# PIC32MX270F512H register map
Vendor: Microchip
Registers are 32-bit, read-write, reset 0x0 unless marked. A register's access mark holds for its fields unless they carry their own. Addresses are absolute, and some are shared; only a register's first bit layout is shown; [hi:lo] are bit positions; {n}, {i} and the like mark numbered series; 'fields as' and 'values as' point back to an identical list.

## CONFIG — Configuration words, addresses in PhysicalSpace
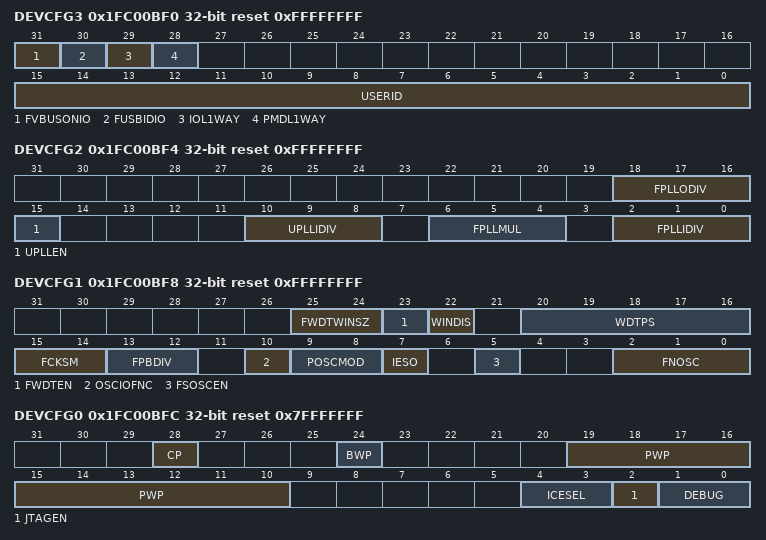
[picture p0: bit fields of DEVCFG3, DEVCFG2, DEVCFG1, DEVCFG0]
0x1FC00BF0 DEVCFG3 reset 0xFFFFFFFF
  [31] FVBUSONIO — USB VBUS ON Selection
    0=OFF (Controlled by Port Function); 1=ON (Controlled by USB Module)
  [30] FUSBIDIO — USB USID Selection
    0=OFF (Controlled by Port Function); 1=ON (Controlled by the USB Module)
  [29] IOL1WAY — Peripheral Pin Select Configuration
    1=ON (Allow only one reconfiguration); 0=OFF (Allow multiple reconfigurations)
  [28] PMDL1WAY — Peripheral Module Disable Configuration
    values as IOL1WAY
  [15:0] USERID
0x1FC00BF4 DEVCFG2 reset 0xFFFFFFFF
  [18:16] FPLLODIV — System PLL Output Clock Divider
    0=DIV_1 (PLL Divide by 1); 1=DIV_2 (PLL Divide by 2); 2=DIV_4 (PLL Divide by 4); 3=DIV_8 (PLL Divide by 8); 4=DIV_16 (PLL Divide by 16); 5=DIV_32 (PLL Divide by 32); 6=DIV_64 (PLL Divide by 64); 7=DIV_256 (PLL Divide by 256)
  [15] UPLLEN — USB PLL Enable
    0=ON (Enabled); 1=OFF (Disabled and Bypassed)
  [10:8] UPLLIDIV — USB PLL Input Divider
    {v}=DIV_{v+1} ({v+1}x Divider) (v=0..5); 6=DIV_10 (10x Divider); 7=DIV_12 (12x Divider)
  [6:4] FPLLMUL — PLL Multiplier
    {v}=MUL_{v+15} ({v+15}x Multiplier) (v=0..6); 7=MUL_24 (24x Multiplier)
  [2:0] FPLLIDIV — PLL Input Divider
    values as UPLLIDIV
0x1FC00BF8 DEVCFG1 reset 0xFFFFFFFF
  [25:24] FWDTWINSZ — Watchdog Timer Window Size
    0=WINSZ_75 (Window Size is 75%); 1=WINSZ_50 (Window Size is 50%); 2=WINSZ_37 (Window Size is 37.5%); 3=WINSZ_25 (Window Size is 25%)
  [23] FWDTEN — Watchdog Timer Enable
    0=OFF (WDT Disabled (SWDTEN Bit Controls)); 1=ON (WDT Enabled)
  [22] WINDIS — Watchdog Timer Window Enable
    0=ON (Watchdog Timer is in Window Mode); 1=OFF (Watchdog Timer is in Non-Window Mode)
  [20:16] WDTPS — Watchdog Timer Postscaler
    0=PS1 (1:1); 1=PS2 (1:2); 2=PS4 (1:4); 3=PS8 (1:8); 4=PS16 (1:16); 5=PS32 (1:32); 6=PS64 (1:64); 7=PS128 (1:128); 8=PS256 (1:256); 9=PS512 (1:512); 10=PS1024 (1:1024); 11=PS2048 (1:2048); 12=PS4096 (1:4096); 13=PS8192 (1:8192); 14=PS16384 (1:16384); 15=PS32768 (1:32768); 0b1x000=PS65536 (1:65536); 0b1x001=PS131072 (1:131072); 0b1x010=PS262144 (1:262144); 0b1x011=PS524288 (1:524288); 0b1x1xx=PS1048576 (1:1048576)
  [15:14] FCKSM — Clock Switching and Monitor Selection
    0=CSECME (Clock Switch Enable, FSCM Enabled); 1=CSECMD (Clock Switch Enable, FSCM Disabled); 3=CSDCMD (Clock Switch Disable, FSCM Disabled)
  [13:12] FPBDIV — Peripheral Clock Divisor
    0=DIV_1 (Pb_Clk is Sys_Clk/1); 1=DIV_2 (Pb_Clk is Sys_Clk/2); 2=DIV_4 (Pb_Clk is Sys_Clk/4); 3=DIV_8 (Pb_Clk is Sys_Clk/8)
  [10] OSCIOFNC — CLKO Output Signal Active on the OSCO Pin
    1=OFF (Disabled); 0=ON (Enabled)
  [9:8] POSCMOD — Primary Oscillator Configuration
    0=EC (External clock mode); 1=XT (XT osc mode); 2=HS (HS osc mode); 3=OFF (Primary osc disabled)
  [7] IESO — Internal/External Switch Over
    0=OFF (Disabled); 1=ON (Enabled)
  [5] FSOSCEN — Secondary Oscillator Enable
    0=OFF (Disabled); 1=ON (Enabled)
  [2:0] FNOSC — Oscillator Selection Bits
    0=FRC (Fast RC Osc (FRC)); 1=FRCPLL (Fast RC Osc with PLL); 2=PRI (Primary Osc (XT,HS,EC)); 3=PRIPLL (Primary Osc w/PLL (XT+,HS+,EC+PLL)); 4=SOSC (Low Power Secondary Osc (SOSC)); 5=LPRC (Low Power RC Osc (LPRC)); 6=FRCDIV16 (Fast RC Osc w/Div-by-16 (FRC/16)); 7=FRCDIV (Fast RC Osc w/Div-by-N (FRCDIV))
0x1FC00BFC DEVCFG0 reset 0x7FFFFFFF
  [28] CP — Code Protect
    0=ON (Protection Enabled); 1=OFF (Protection Disabled)
  [24] BWP — Boot Flash Write Protect bit
    0=ON (Protection Enabled); 1=OFF (Protection Disabled)
  [19:10] PWP — Program Flash Write Protect
    0x3FF=OFF (Disable); 0x3FE=PWP1K (First 1K); 0x3FD=PWP2K (First 2K); 0x3FC=PWP3K (First 3K); 0x3FB=PWP4K (First 4K); 0x3FA=PWP5K (First 5K); 0x3F9=PWP6K (First 6K); 0x3F8=PWP7K (First 7K); 0x3F7=PWP8K (First 8K); 0x3F6=PWP9K (First 9K); 0x3F5=PWP10K (First 10K); 0x3F4=PWP11K (First 11K); 0x3F3=PWP12K (First 12K); 0x3F2=PWP13K (First 13K); 0x3F1=PWP14K (First 14K); 0x3F0=PWP15K (First 15K); 0x3EF=PWP16K (First 16K); 0x3EE=PWP17K (First 17K); 0x3ED=PWP18K (First 18K); 0x3EC=PWP19K (First 19K); 0x3EB=PWP20K (First 20K); 0x3EA=PWP21K (First 21K); 0x3E9=PWP22K (First 22K); 0x3E8=PWP23K (First 23K); 0x3E7=PWP24K (First 24K); 0x3E6=PWP25K (First 25K); 0x3E5=PWP26K (First 26K); 0x3E4=PWP27K (First 27K); 0x3E3=PWP28K (First 28K); 0x3E2=PWP29K (First 29K); 0x3E1=PWP30K (First 30K); 0x3E0=PWP31K (First 31K); 0x3DF=PWP32K (First 32K); 0x3DE=PWP33K (First 33K); 0x3DD=PWP34K (First 34K); 0x3DC=PWP35K (First 35K); 0x3DB=PWP36K (First 36K); 0x3DA=PWP37K (First 37K); 0x3D9=PWP38K (First 38K); 0x3D8=PWP39K (First 39K); 0x3D7=PWP40K (First 40K); 0x3D6=PWP41K (First 41K); 0x3D5=PWP42K (First 42K); 0x3D4=PWP43K (First 43K); 0x3D3=PWP44K (First 44K); 0x3D2=PWP45K (First 45K); 0x3D1=PWP46K (First 46K); 0x3D0=PWP47K (First 47K); 0x3CF=PWP48K (First 48K); 0x3CE=PWP49K (First 49K); 0x3CD=PWP50K (First 50K); 0x3CC=PWP51K (First 51K); 0x3CB=PWP52K (First 52K); 0x3CA=PWP53K (First 53K); 0x3C9=PWP54K (First 54K); 0x3C8=PWP55K (First 55K); 0x3C7=PWP56K (First 56K); 0x3C6=PWP57K (First 57K); 0x3C5=PWP58K (First 58K); 0x3C4=PWP59K (First 59K); 0x3C3=PWP60K (First 60K); 0x3C2=PWP61K (First 61K); 0x3C1=PWP62K (First 62K); 0x3C0=PWP63K (First 63K); 0x3BF=PWP64K (First 64K); 0x3BE=PWP65K (First 65K); 0x3BD=PWP66K (First 66K); 0x3BC=PWP67K (First 67K); 0x3BB=PWP68K (First 68K); 0x3BA=PWP69K (First 69K); 0x3B9=PWP70K (First 70K); 0x3B8=PWP71K (First 71K); 0x3B7=PWP72K (First 72K); 0x3B6=PWP73K (First 73K); 0x3B5=PWP74K (First 74K); 0x3B4=PWP75K (First 75K); 0x3B3=PWP76K (First 76K); 0x3B2=PWP77K (First 77K); 0x3B1=PWP78K (First 78K); 0x3B0=PWP79K (First 79K); 0x3AF=PWP80K (First 80K); 0x3AE=PWP81K (First 81K); 0x3AD=PWP82K (First 82K); 0x3AC=PWP83K (First 83K); 0x3AB=PWP84K (First 84K); 0x3AA=PWP85K (First 85K); 0x3A9=PWP86K (First 86K); 0x3A8=PWP87K (First 87K); 0x3A7=PWP88K (First 88K); 0x3A6=PWP89K (First 89K); 0x3A5=PWP90K (First 90K); 0x3A4=PWP91K (First 91K); 0x3A3=PWP92K (First 92K); 0x3A2=PWP93K (First 93K); 0x3A1=PWP94K (First 94K); 0x3A0=PWP95K (First 95K); 0x39F=PWP96K (First 96K); 0x39E=PWP97K (First 97K); 0x39D=PWP98K (First 98K); 0x39C=PWP99K (First 99K); 0x39B=PWP100K (First 100K); 0x39A=PWP101K (First 101K); 0x399=PWP102K (First 102K); 0x398=PWP103K (First 103K); 0x397=PWP104K (First 104K); 0x396=PWP105K (First 105K); 0x395=PWP106K (First 106K); 0x394=PWP107K (First 107K); 0x393=PWP108K (First 108K); 0x392=PWP109K (First 109K); 0x391=PWP110K (First 110K); 0x390=PWP111K (First 111K); 0x38F=PWP112K (First 112K); 0x38E=PWP113K (First 113K); 0x38D=PWP114K (First 114K); 0x38C=PWP115K (First 115K); 0x38B=PWP116K (First 116K); 0x38A=PWP117K (First 117K); 0x389=PWP118K (First 118K); 0x388=PWP119K (First 119K); 0x387=PWP120K (First 120K); 0x386=PWP121K (First 121K); 0x385=PWP122K (First 122K); 0x384=PWP123K (First 123K); 0x383=PWP124K (First 124K); 0x382=PWP125K (First 125K); 0x381=PWP126K (First 126K); 0x380=PWP127K (First 127K); 0x37F=PWP128K (First 128K); 0x37E=PWP129K (First 129K); 0x37D=PWP130K (First 130K); 0x37C=PWP131K (First 131K); 0x37B=PWP132K (First 132K); 0x37A=PWP133K (First 133K); 0x379=PWP134K (First 134K); 0x378=PWP135K (First 135K); 0x377=PWP136K (First 136K); 0x376=PWP137K (First 137K); 0x375=PWP138K (First 138K); 0x374=PWP139K (First 139K); 0x373=PWP140K (First 140K); 0x372=PWP141K (First 141K); 0x371=PWP142K (First 142K); 0x370=PWP143K (First 143K); 0x36F=PWP144K (First 144K); 0x36E=PWP145K (First 145K); 0x36D=PWP146K (First 146K); 0x36C=PWP147K (First 147K); 0x36B=PWP148K (First 148K); 0x36A=PWP149K (First 149K); 0x369=PWP150K (First 150K); 0x368=PWP151K (First 151K); 0x367=PWP152K (First 152K); 0x366=PWP153K (First 153K); 0x365=PWP154K (First 154K); 0x364=PWP155K (First 155K); 0x363=PWP156K (First 156K); 0x362=PWP157K (First 157K); 0x361=PWP158K (First 158K); 0x360=PWP159K (First 159K); 0x35F=PWP160K (First 160K); 0x35E=PWP161K (First 161K); 0x35D=PWP162K (First 162K); 0x35C=PWP163K (First 163K); 0x35B=PWP164K (First 164K); 0x35A=PWP165K (First 165K); 0x359=PWP166K (First 166K); 0x358=PWP167K (First 167K); 0x357=PWP168K (First 168K); 0x356=PWP169K (First 169K); 0x355=PWP170K (First 170K); 0x354=PWP171K (First 171K); 0x353=PWP172K (First 172K); 0x352=PWP173K (First 173K); 0x351=PWP174K (First 174K); 0x350=PWP175K (First 175K); 0x34F=PWP176K (First 176K); 0x34E=PWP177K (First 177K); 0x34D=PWP178K (First 178K); 0x34C=PWP179K (First 179K); 0x34B=PWP180K (First 180K); 0x34A=PWP181K (First 181K); 0x349=PWP182K (First 182K); 0x348=PWP183K (First 183K); 0x347=PWP184K (First 184K); 0x346=PWP185K (First 185K); 0x345=PWP186K (First 186K); 0x344=PWP187K (First 187K); 0x343=PWP188K (First 188K); 0x342=PWP189K (First 189K); 0x341=PWP190K (First 190K); 0x340=PWP191K (First 191K); 0x33F=PWP192K (First 192K); 0x33E=PWP193K (First 193K); 0x33D=PWP194K (First 194K); 0x33C=PWP195K (First 195K); 0x33B=PWP196K (First 196K); 0x33A=PWP197K (First 197K); 0x339=PWP198K (First 198K); 0x338=PWP199K (First 199K); 0x337=PWP200K (First 200K); 0x336=PWP201K (First 201K); 0x335=PWP202K (First 202K); 0x334=PWP203K (First 203K); 0x333=PWP204K (First 204K); 0x332=PWP205K (First 205K); 0x331=PWP206K (First 206K); 0x330=PWP207K (First 207K); 0x32F=PWP208K (First 208K); 0x32E=PWP209K (First 209K); 0x32D=PWP210K (First 210K); 0x32C=PWP211K (First 211K); 0x32B=PWP212K (First 212K); 0x32A=PWP213K (First 213K); 0x329=PWP214K (First 214K); 0x328=PWP215K (First 215K); 0x327=PWP216K (First 216K); 0x326=PWP217K (First 217K); 0x325=PWP218K (First 218K); 0x324=PWP219K (First 219K); 0x323=PWP220K (First 220K); 0x322=PWP221K (First 221K); 0x321=PWP222K (First 222K); 0x320=PWP223K (First 223K); 0x31F=PWP224K (First 224K); 0x31E=PWP225K (First 225K); 0x31D=PWP226K (First 226K); 0x31C=PWP227K (First 227K); 0x31B=PWP228K (First 228K); 0x31A=PWP229K (First 229K); 0x319=PWP230K (First 230K); 0x318=PWP231K (First 231K); 0x317=PWP232K (First 232K); 0x316=PWP233K (First 233K); 0x315=PWP234K (First 234K); 0x314=PWP235K (First 235K); 0x313=PWP236K (First 236K); 0x312=PWP237K (First 237K); 0x311=PWP238K (First 238K); 0x310=PWP239K (First 239K); 0x30F=PWP240K (First 240K); 0x30E=PWP241K (First 241K); 0x30D=PWP242K (First 242K); 0x30C=PWP243K (First 243K); 0x30B=PWP244K (First 244K); 0x30A=PWP245K (First 245K); 0x309=PWP246K (First 246K); 0x308=PWP247K (First 247K); 0x307=PWP248K (First 248K); 0x306=PWP249K (First 249K); 0x305=PWP250K (First 250K); 0x304=PWP251K (First 251K); 0x303=PWP252K (First 252K); 0x302=PWP253K (First 253K); 0x301=PWP254K (First 254K); 0x300=PWP255K (First 255K); 0x2FF=PWP256K (First 256K); 0x2FE=PWP257K (First 257K); 0x2FD=PWP258K (First 258K); 0x2FC=PWP259K (First 259K); 0x2FB=PWP260K (First 260K); 0x2FA=PWP261K (First 261K); 0x2F9=PWP262K (First 262K); 0x2F8=PWP263K (First 263K); 0x2F7=PWP264K (First 264K); 0x2F6=PWP265K (First 265K); 0x2F5=PWP266K (First 266K); 0x2F4=PWP267K (First 267K); 0x2F3=PWP268K (First 268K); 0x2F2=PWP269K (First 269K); 0x2F1=PWP270K (First 270K); 0x2F0=PWP271K (First 271K); 0x2EF=PWP272K (First 272K); 0x2EE=PWP273K (First 273K); 0x2ED=PWP274K (First 274K); 0x2EC=PWP275K (First 275K); 0x2EB=PWP276K (First 276K); 0x2EA=PWP277K (First 277K); 0x2E9=PWP278K (First 278K); 0x2E8=PWP279K (First 279K); 0x2E7=PWP280K (First 280K); 0x2E6=PWP281K (First 281K); 0x2E5=PWP282K (First 282K); 0x2E4=PWP283K (First 283K); 0x2E3=PWP284K (First 284K); 0x2E2=PWP285K (First 285K); 0x2E1=PWP286K (First 286K); 0x2E0=PWP287K (First 287K); 0x2DF=PWP288K (First 288K); 0x2DE=PWP289K (First 289K); 0x2DD=PWP290K (First 290K); 0x2DC=PWP291K (First 291K); 0x2DB=PWP292K (First 292K); 0x2DA=PWP293K (First 293K); 0x2D9=PWP294K (First 294K); 0x2D8=PWP295K (First 295K); 0x2D7=PWP296K (First 296K); 0x2D6=PWP297K (First 297K); 0x2D5=PWP298K (First 298K); 0x2D4=PWP299K (First 299K); 0x2D3=PWP300K (First 300K); 0x2D2=PWP301K (First 301K); 0x2D1=PWP302K (First 302K); 0x2D0=PWP303K (First 303K); 0x2CF=PWP304K (First 304K); 0x2CE=PWP305K (First 305K); 0x2CD=PWP306K (First 306K); 0x2CC=PWP307K (First 307K); 0x2CB=PWP308K (First 308K); 0x2CA=PWP309K (First 309K); 0x2C9=PWP310K (First 310K); 0x2C8=PWP311K (First 311K); 0x2C7=PWP312K (First 312K); 0x2C6=PWP313K (First 313K); 0x2C5=PWP314K (First 314K); 0x2C4=PWP315K (First 315K); 0x2C3=PWP316K (First 316K); 0x2C2=PWP317K (First 317K); 0x2C1=PWP318K (First 318K); 0x2C0=PWP319K (First 319K); 0x2BF=PWP320K (First 320K); 0x2BE=PWP321K (First 321K); 0x2BD=PWP322K (First 322K); 0x2BC=PWP323K (First 323K); 0x2BB=PWP324K (First 324K); 0x2BA=PWP325K (First 325K); 0x2B9=PWP326K (First 326K); 0x2B8=PWP327K (First 327K); 0x2B7=PWP328K (First 328K); 0x2B6=PWP329K (First 329K); 0x2B5=PWP330K (First 330K); 0x2B4=PWP331K (First 331K); 0x2B3=PWP332K (First 332K); 0x2B2=PWP333K (First 333K); 0x2B1=PWP334K (First 334K); 0x2B0=PWP335K (First 335K); 0x2AF=PWP336K (First 336K); 0x2AE=PWP337K (First 337K); 0x2AD=PWP338K (First 338K); 0x2AC=PWP339K (First 339K); 0x2AB=PWP340K (First 340K); 0x2AA=PWP341K (First 341K); 0x2A9=PWP342K (First 342K); 0x2A8=PWP343K (First 343K); 0x2A7=PWP344K (First 344K); 0x2A6=PWP345K (First 345K); 0x2A5=PWP346K (First 346K); 0x2A4=PWP347K (First 347K); 0x2A3=PWP348K (First 348K); 0x2A2=PWP349K (First 349K); 0x2A1=PWP350K (First 350K); 0x2A0=PWP351K (First 351K); 0x29F=PWP352K (First 352K); 0x29E=PWP353K (First 353K); 0x29D=PWP354K (First 354K); 0x29C=PWP355K (First 355K); 0x29B=PWP356K (First 356K); 0x29A=PWP357K (First 357K); 0x299=PWP358K (First 358K); 0x298=PWP359K (First 359K); 0x297=PWP360K (First 360K); 0x296=PWP361K (First 361K); 0x295=PWP362K (First 362K); 0x294=PWP363K (First 363K); 0x293=PWP364K (First 364K); 0x292=PWP365K (First 365K); 0x291=PWP366K (First 366K); 0x290=PWP367K (First 367K); 0x28F=PWP368K (First 368K); 0x28E=PWP369K (First 369K); 0x28D=PWP370K (First 370K); 0x28C=PWP371K (First 371K); 0x28B=PWP372K (First 372K); 0x28A=PWP373K (First 373K); 0x289=PWP374K (First 374K); 0x288=PWP375K (First 375K); 0x287=PWP376K (First 376K); 0x286=PWP377K (First 377K); 0x285=PWP378K (First 378K); 0x284=PWP379K (First 379K); 0x283=PWP380K (First 380K); 0x282=PWP381K (First 381K); 0x281=PWP382K (First 382K); 0x280=PWP383K (First 383K); 0x27F=PWP384K (First 384K); 0x27E=PWP385K (First 385K); 0x27D=PWP386K (First 386K); 0x27C=PWP387K (First 387K); 0x27B=PWP388K (First 388K); 0x27A=PWP389K (First 389K); 0x279=PWP390K (First 390K); 0x278=PWP391K (First 391K); 0x277=PWP392K (First 392K); 0x276=PWP393K (First 393K); 0x275=PWP394K (First 394K); 0x274=PWP395K (First 395K); 0x273=PWP396K (First 396K); 0x272=PWP397K (First 397K); 0x271=PWP398K (First 398K); 0x270=PWP399K (First 399K); 0x26F=PWP400K (First 400K); 0x26E=PWP401K (First 401K); 0x26D=PWP402K (First 402K); 0x26C=PWP403K (First 403K); 0x26B=PWP404K (First 404K); 0x26A=PWP405K (First 405K); 0x269=PWP406K (First 406K); 0x268=PWP407K (First 407K); 0x267=PWP408K (First 408K); 0x266=PWP409K (First 409K); 0x265=PWP410K (First 410K); 0x264=PWP411K (First 411K); 0x263=PWP412K (First 412K); 0x262=PWP413K (First 413K); 0x261=PWP414K (First 414K); 0x260=PWP415K (First 415K); 0x25F=PWP416K (First 416K); 0x25E=PWP417K (First 417K); 0x25D=PWP418K (First 418K); 0x25C=PWP419K (First 419K); 0x25B=PWP420K (First 420K); 0x25A=PWP421K (First 421K); 0x259=PWP422K (First 422K); 0x258=PWP423K (First 423K); 0x257=PWP424K (First 424K); 0x256=PWP425K (First 425K); 0x255=PWP426K (First 426K); 0x254=PWP427K (First 427K); 0x253=PWP428K (First 428K); 0x252=PWP429K (First 429K); 0x251=PWP430K (First 430K); 0x250=PWP431K (First 431K); 0x24F=PWP432K (First 432K); 0x24E=PWP433K (First 433K); 0x24D=PWP434K (First 434K); 0x24C=PWP435K (First 435K); 0x24B=PWP436K (First 436K); 0x24A=PWP437K (First 437K); 0x249=PWP438K (First 438K); 0x248=PWP439K (First 439K); 0x247=PWP440K (First 440K); 0x246=PWP441K (First 441K); 0x245=PWP442K (First 442K); 0x244=PWP443K (First 443K); 0x243=PWP444K (First 444K); 0x242=PWP445K (First 445K); 0x241=PWP446K (First 446K); 0x240=PWP447K (First 447K); 0x23F=PWP448K (First 448K); 0x23E=PWP449K (First 449K); 0x23D=PWP450K (First 450K); 0x23C=PWP451K (First 451K); 0x23B=PWP452K (First 452K); 0x23A=PWP453K (First 453K); 0x239=PWP454K (First 454K); 0x238=PWP455K (First 455K); 0x237=PWP456K (First 456K); 0x236=PWP457K (First 457K); 0x235=PWP458K (First 458K); 0x234=PWP459K (First 459K); 0x233=PWP460K (First 460K); 0x232=PWP461K (First 461K); 0x231=PWP462K (First 462K); 0x230=PWP463K (First 463K); 0x22F=PWP464K (First 464K); 0x22E=PWP465K (First 465K); 0x22D=PWP466K (First 466K); 0x22C=PWP467K (First 467K); 0x22B=PWP468K (First 468K); 0x22A=PWP469K (First 469K); 0x229=PWP470K (First 470K); 0x228=PWP471K (First 471K); 0x227=PWP472K (First 472K); 0x226=PWP473K (First 473K); 0x225=PWP474K (First 474K); 0x224=PWP475K (First 475K); 0x223=PWP476K (First 476K); 0x222=PWP477K (First 477K); 0x221=PWP478K (First 478K); 0x220=PWP479K (First 479K); 0x21F=PWP480K (First 480K); 0x21E=PWP481K (First 481K); 0x21D=PWP482K (First 482K); 0x21C=PWP483K (First 483K); 0x21B=PWP484K (First 484K); 0x21A=PWP485K (First 485K); 0x219=PWP486K (First 486K); 0x218=PWP487K (First 487K); 0x217=PWP488K (First 488K); 0x216=PWP489K (First 489K); 0x215=PWP490K (First 490K); 0x214=PWP491K (First 491K); 0x213=PWP492K (First 492K); 0x212=PWP493K (First 493K); 0x211=PWP494K (First 494K); 0x210=PWP495K (First 495K); 0x20F=PWP496K (First 496K); 0x20E=PWP497K (First 497K); 0x20D=PWP498K (First 498K); 0x20C=PWP499K (First 499K); 0x20B=PWP500K (First 500K); 0x20A=PWP501K (First 501K); 0x209=PWP502K (First 502K); 0x208=PWP503K (First 503K); 0x207=PWP504K (First 504K); 0x206=PWP505K (First 505K); 0x205=PWP506K (First 506K); 0x204=PWP507K (First 507K); 0x203=PWP508K (First 508K); 0x202=PWP509K (First 509K); 0x201=PWP510K (First 510K); 0x200=PWP511K (First 511K); 0x1FF=PWP512K (First 512K)
  [4:3] ICESEL — ICE/ICD Comm Channel Select
    3=ICS_PGx1 (Communicate on PGEC1/PGED1); 2=ICS_PGx2 (Communicate on PGEC2/PGED2); 1=ICS_PGx3 (Communicate on PGEC3/PGED3); 0=ICS_PGx4 (Communicate on PGEC4/PGED4)
  [2] JTAGEN — JTAG Enable
    1=ON (JTAG Port Enabled); 0=OFF (JTAG Disabled)
  [1:0] DEBUG — Background Debugger Enable
    0=ON (Debugger is Enabled); 3=OFF (Debugger is Disabled)
